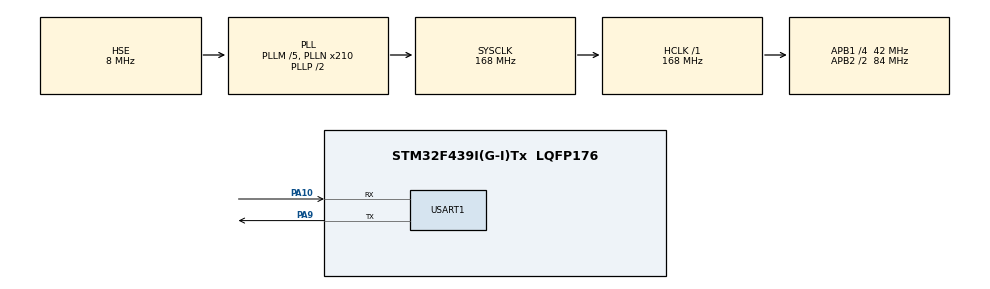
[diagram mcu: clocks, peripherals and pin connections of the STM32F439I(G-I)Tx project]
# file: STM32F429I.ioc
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ADC1.Channel-14\#ChannelRegularConversion=ADC_CHANNEL_TEMPSENSOR
ADC1.NbrOfConversionFlag=1
ADC1.Rank-14\#ChannelRegularConversion=1
ADC1.SamplingTime-14\#ChannelRegularConversion=ADC_SAMPLETIME_3CYCLES
ADC1.master=1
Mcu.Family=STM32F4
Mcu.Name=STM32F439I(G-I)Tx
Mcu.Package=LQFP176
NVIC.PriorityGroup=NVIC_PRIORITYGROUP_4
PA10.Mode=Asynchronous
PA10.Signal=USART1_RX
PA9.Mode=Asynchronous
PA9.Signal=USART1_TX
PH0/OSC_IN.Mode=HSE-External-Oscillator
PH0/OSC_IN.Signal=RCC_OSC_IN
PH1/OSC_OUT.Mode=HSE-External-Oscillator
PH1/OSC_OUT.Signal=RCC_OSC_OUT
ProjectManager.TargetToolchain=MDK-ARM V5
RCC.48MHZClocksFreq_Value=84000000
RCC.AHBFreq_Value=168000000
RCC.APB1CLKDivider=RCC_HCLK_DIV4
RCC.APB1Freq_Value=42000000
RCC.APB1TimFreq_Value=84000000
RCC.APB2CLKDivider=RCC_HCLK_DIV2
RCC.APB2Freq_Value=84000000
RCC.APB2TimFreq_Value=168000000
RCC.CortexFreq_Value=168000000
RCC.HCLKFreq_Value=168000000
RCC.HSE_VALUE=8000000
RCC.HSI_VALUE=16000000
RCC.LSE_VALUE=32768
RCC.PLLM=5
RCC.PLLN=210
RCC.PLLSourceVirtual=RCC_PLLSOURCE_HSE
RCC.SYSCLKFreq_VALUE=168000000
RCC.SYSCLKSource=RCC_SYSCLKSOURCE_PLLCLK
RCC.VCOOutputFreq_Value=336000000
VP_ADC1_TempSens_Input.Mode=IN-TempSens
board=STM32F429I

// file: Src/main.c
/**
  ******************************************************************************
  * File Name          : main.c
  * Description        : Main program body
  ******************************************************************************
  *
  * COPYRIGHT(c) 2015 STMicroelectronics
  *
  * Redistribution and use in source and binary forms, with or without modification,
  * are permitted provided that the following conditions are met:
  *   1. Redistributions of source code must retain the above copyright notice,
  *      this list of conditions and the following disclaimer.
  *   2. Redistributions in binary form must reproduce the above copyright notice,
  *      this list of conditions and the following disclaimer in the documentation
  *      and/or other materials provided with the distribution.
  *   3. Neither the name of STMicroelectronics nor the names of its contributors
  *      may be used to endorse or promote products derived from this software
  *      without specific prior written permission.
  *
  * THIS SOFTWARE IS PROVIDED BY THE COPYRIGHT HOLDERS AND CONTRIBUTORS "AS IS"
  * AND ANY EXPRESS OR IMPLIED WARRANTIES, INCLUDING, BUT NOT LIMITED TO, THE
  * IMPLIED WARRANTIES OF MERCHANTABILITY AND FITNESS FOR A PARTICULAR PURPOSE ARE
  * DISCLAIMED. IN NO EVENT SHALL THE COPYRIGHT HOLDER OR CONTRIBUTORS BE LIABLE
  * FOR ANY DIRECT, INDIRECT, INCIDENTAL, SPECIAL, EXEMPLARY, OR CONSEQUENTIAL
  * DAMAGES (INCLUDING, BUT NOT LIMITED TO, PROCUREMENT OF SUBSTITUTE GOODS OR
  * SERVICES; LOSS OF USE, DATA, OR PROFITS; OR BUSINESS INTERRUPTION) HOWEVER
  * CAUSED AND ON ANY THEORY OF LIABILITY, WHETHER IN CONTRACT, STRICT LIABILITY,
  * OR TORT (INCLUDING NEGLIGENCE OR OTHERWISE) ARISING IN ANY WAY OUT OF THE USE
  * OF THIS SOFTWARE, EVEN IF ADVISED OF THE POSSIBILITY OF SUCH DAMAGE.
  *
  ******************************************************************************
  */
#include "stm32f4xx_hal.h"

ADC_HandleTypeDef hadc1;

UART_HandleTypeDef huart1;

/* USER CODE BEGIN PV */
/* Private variables ---------------------------------------------------------*/
uint16_t AD_Value;

/* USER CODE END PV */

void SystemClock_Config(void);
static void MX_GPIO_Init(void);
static void MX_ADC1_Init(void);
static void MX_USART1_UART_Init(void);

/* USER CODE BEGIN PFP */
/* Private function prototypes -----------------------------------------------*/

/* USER CODE END PFP */

/* USER CODE BEGIN 0 */
/**
  * @brief  Retargets the C library printf function to the USART.
  * @param  None
  * @retval None
  */
int fputc(int ch, FILE *f)
{
  /* write a character to the uart1 and Loop until the end of transmission */
  HAL_UART_Transmit(&huart1, (uint8_t *)&ch, 1, 0xFFFF);

  return ch;
}

/* USER CODE END 0 */

int main(void)
{

  /* MCU Configuration----------------------------------------------------------*/

  /* Reset of all peripherals, Initializes the Flash interface and the Systick. */
  HAL_Init();

  /* Configure the system clock */
  SystemClock_Config();

  /* Initialize all configured peripherals */
  MX_GPIO_Init();
  MX_ADC1_Init();
  MX_USART1_UART_Init();

  /* Infinite loop */
  while (1)
  {

  /* USER CODE BEGIN 3 */

		/*##-1- Start the conversion process #######################################*/
		HAL_ADC_Start(&hadc1);

		/*##-2- Wait for the end of conversion #####################################*/
		 /*  Before starting a new conversion, you need to check the current state of
					the peripheral; if it�s busy you need to wait for the end of current
					conversion before starting a new one.
					For simplicity reasons, this example is just waiting till the end of the
					conversion, but application may perform other tasks while conversion
					operation is ongoing. */
		HAL_ADC_PollForConversion(&hadc1, 10);

		/* Check if the continous conversion of regular channel is finished */
		if(HAL_ADC_GetState(&hadc1) == HAL_ADC_STATE_EOC_REG)
		{
			/*##-3- Get the converted value of regular channel  ######################*/
			AD_Value = HAL_ADC_GetValue(&hadc1);
		}
		printf("MCU Temperature : %.1f��\r\n",((AD_Value*3300/4096-760)/2.5+25));

		HAL_Delay(1000);
  }
  /* USER CODE END 3 */

}

/** System Clock Configuration
*/
void SystemClock_Config(void)
{

  RCC_OscInitTypeDef RCC_OscInitStruct;
  RCC_ClkInitTypeDef RCC_ClkInitStruct;

  __PWR_CLK_ENABLE();

  __HAL_PWR_VOLTAGESCALING_CONFIG(PWR_REGULATOR_VOLTAGE_SCALE1);

  RCC_OscInitStruct.OscillatorType = RCC_OSCILLATORTYPE_HSE;
  RCC_OscInitStruct.HSEState = RCC_HSE_ON;
  RCC_OscInitStruct.PLL.PLLState = RCC_PLL_ON;
  RCC_OscInitStruct.PLL.PLLSource = RCC_PLLSOURCE_HSE;
  RCC_OscInitStruct.PLL.PLLM = 5;
  RCC_OscInitStruct.PLL.PLLN = 210;
  RCC_OscInitStruct.PLL.PLLP = RCC_PLLP_DIV2;
  RCC_OscInitStruct.PLL.PLLQ = 4;
  HAL_RCC_OscConfig(&RCC_OscInitStruct);

  RCC_ClkInitStruct.ClockType = RCC_CLOCKTYPE_SYSCLK|RCC_CLOCKTYPE_PCLK1
                              |RCC_CLOCKTYPE_PCLK2;
  RCC_ClkInitStruct.SYSCLKSource = RCC_SYSCLKSOURCE_PLLCLK;
  RCC_ClkInitStruct.AHBCLKDivider = RCC_SYSCLK_DIV1;
  RCC_ClkInitStruct.APB1CLKDivider = RCC_HCLK_DIV4;
  RCC_ClkInitStruct.APB2CLKDivider = RCC_HCLK_DIV2;
  HAL_RCC_ClockConfig(&RCC_ClkInitStruct, FLASH_LATENCY_5);

  HAL_SYSTICK_Config(HAL_RCC_GetHCLKFreq()/1000);

  HAL_SYSTICK_CLKSourceConfig(SYSTICK_CLKSOURCE_HCLK);

}

/* ADC1 init function */
void MX_ADC1_Init(void)
{

  ADC_ChannelConfTypeDef sConfig;

    /**Configure the global features of the ADC (Clock, Resolution, Data Alignment and number of conversion)
    */
  hadc1.Instance = ADC1;
  hadc1.Init.ClockPrescaler = ADC_CLOCKPRESCALER_PCLK_DIV4;
  hadc1.Init.Resolution = ADC_RESOLUTION12b;
  hadc1.Init.ScanConvMode = DISABLE;
  hadc1.Init.ContinuousConvMode = DISABLE;
  hadc1.Init.DiscontinuousConvMode = DISABLE;
  hadc1.Init.ExternalTrigConvEdge = ADC_EXTERNALTRIGCONVEDGE_NONE;
  hadc1.Init.DataAlign = ADC_DATAALIGN_RIGHT;
  hadc1.Init.NbrOfConversion = 1;
  hadc1.Init.DMAContinuousRequests = DISABLE;
  hadc1.Init.EOCSelection = EOC_SINGLE_CONV;
  HAL_ADC_Init(&hadc1);

    /**Configure for the selected ADC regular channel its corresponding rank in the sequencer and its sample time.
    */
  sConfig.Channel = ADC_CHANNEL_TEMPSENSOR;
  sConfig.Rank = 1;
  sConfig.SamplingTime = ADC_SAMPLETIME_3CYCLES;
  HAL_ADC_ConfigChannel(&hadc1, &sConfig);

}

/* USART1 init function */
void MX_USART1_UART_Init(void)
{

  huart1.Instance = USART1;
  huart1.Init.BaudRate = 115200;
  huart1.Init.WordLength = UART_WORDLENGTH_8B;
  huart1.Init.StopBits = UART_STOPBITS_1;
  huart1.Init.Parity = UART_PARITY_NONE;
  huart1.Init.Mode = UART_MODE_TX_RX;
  huart1.Init.HwFlowCtl = UART_HWCONTROL_NONE;
  huart1.Init.OverSampling = UART_OVERSAMPLING_16;
  HAL_UART_Init(&huart1);

}

/** Configure pins as
        * Analog
        * Input
        * Output
        * EVENT_OUT
        * EXTI
*/
void MX_GPIO_Init(void)
{

  /* GPIO Ports Clock Enable */
  __GPIOH_CLK_ENABLE();
  __GPIOA_CLK_ENABLE();

}

/************************ (C) COPYRIGHT STMicroelectronics *****END OF FILE****/
